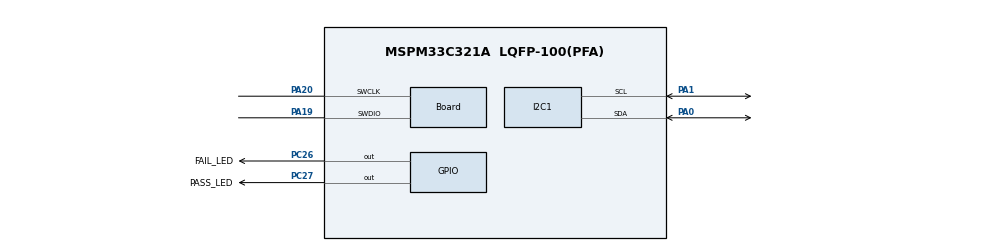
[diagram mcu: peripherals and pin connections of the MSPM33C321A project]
//@cliArgs --device "MSPM33C321A" --package "LQFP-100(PFA)" --part "Default"
//@v2CliArgs --device "MSPM33C321A" --package "LQFP-100(PFA)"
// @cliArgs --board /ti/boards/LP_MSPM33C321A --rtos nortos


/**
 * Import the modules used in this configuration.
 */
const GPIO   = scripting.addModule("/ti/driverlib/GPIO", {}, false);
const GPIO1  = GPIO.addInstance();
const I2C    = scripting.addModule("/ti/driverlib/I2C", {}, false);
const I2C1   = I2C.addInstance();
const SYSCTL = scripting.addModule("/ti/driverlib/SYSCTL");


/**
 * Write custom configuration values to the imported modules.
 */
GPIO1.$name                                 = "GPIO_LEDS";
GPIO1.associatedPins.create(2);
GPIO1.associatedPins[0].$name               = "FAIL_LED";
GPIO1.associatedPins[0].assignedPort        = "PORTC";
GPIO1.associatedPins[0].assignedPortSegment = "Upper";
GPIO1.associatedPins[0].assignedPin         = "26";
GPIO1.associatedPins[0].launchPadShortcut   = "LED2RedEn";
GPIO1.associatedPins[0].pin.$assign         = "PC26";
GPIO1.associatedPins[1].$name               = "PASS_LED";
GPIO1.associatedPins[1].launchPadShortcut   = "LED2GreenEn";
GPIO1.associatedPins[1].pin.$assign         = "PC27";

const Board                       = scripting.addModule("/ti/driverlib/Board", {}, false);
Board.peripheral.$assign          = "DEBUGSS";
Board.peripheral.swclkPin.$assign = "PA20";
Board.peripheral.swdioPin.$assign = "PA19";

I2C1.basicTargetAddress                = 0x50;
I2C1.advTargetTXFIFOTRIG               = "ALMOST_EMPTY";
I2C1.$name                             = "I2C";
I2C1.basicEnableController             = true;
I2C1.intController                     = ["NACK","RXFIFO_TRIGGER","RX_DONE","TX_DONE"];
I2C1.basicControllerBusSpeed           = 40000;
I2C1.peripheral.$assign                = "UC15_0";
I2C1.peripheral.sdaPin.$assign         = "PA0";
I2C1.peripheral.sclPin.$assign         = "PA1";
I2C1.sdaPinConfig.$name                = "ti_driverlib_gpio_GPIOPinGeneric0";
I2C1.sdaPinConfig.enableConfig         = true;
I2C1.sclPinConfig.$name                = "ti_driverlib_gpio_GPIOPinGeneric1";
I2C1.sclPinConfig.enableConfig         = true;

SYSCTL.forceDefaultClkConfig = true;
SYSCTL.peripheral.$assign    = "SYSCTL";

const ProjectConfig              = scripting.addModule("/ti/project_config/ProjectConfig", {}, false);
ProjectConfig.migrationCondition = true;

ProjectConfig.genLinker  = true;
ProjectConfig.genStartup = true;
ProjectConfig.genOpts    = true;
ProjectConfig.genLibs    = true;
